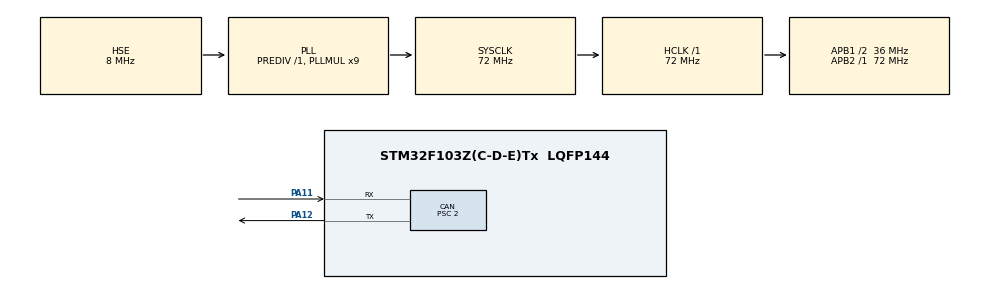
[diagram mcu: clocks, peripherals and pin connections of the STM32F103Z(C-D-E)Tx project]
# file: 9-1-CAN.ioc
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CAN.ABOM=ENABLE
CAN.BS1=CAN_BS1_13TQ
CAN.BS2=CAN_BS2_4TQ
CAN.CalculateBaudRate=1000000
CAN.CalculateTimeBit=1000
CAN.CalculateTimeQuantum=55.55555555555556
CAN.NART=ENABLE
CAN.Prescaler=2
Mcu.Family=STM32F1
Mcu.Name=STM32F103Z(C-D-E)Tx
Mcu.Package=LQFP144
NVIC.CAN1_RX1_IRQn=true\:0\:0\:false\:false\:true\:true\:true\:true
NVIC.CAN1_SCE_IRQn=true\:0\:0\:false\:false\:true\:true\:true\:true
NVIC.PriorityGroup=NVIC_PRIORITYGROUP_4
OSC_IN.Mode=HSE-External-Oscillator
OSC_IN.Signal=RCC_OSC_IN
OSC_OUT.Mode=HSE-External-Oscillator
OSC_OUT.Signal=RCC_OSC_OUT
PA11.Mode=CAN_Activate
PA11.Signal=CAN_RX
PA12.Mode=CAN_Activate
PA12.Signal=CAN_TX
PA13.Mode=Serial_Wire
PA13.Signal=SYS_JTMS-SWDIO
PA14.Mode=Serial_Wire
PA14.Signal=SYS_JTCK-SWCLK
ProjectManager.HeapSize=0x200
ProjectManager.StackSize=0x400
ProjectManager.TargetToolchain=MDK-ARM V5.32
RCC.AHBFreq_Value=72000000
RCC.APB1CLKDivider=RCC_HCLK_DIV2
RCC.APB1Freq_Value=36000000
RCC.APB1TimFreq_Value=72000000
RCC.APB2Freq_Value=72000000
RCC.APB2TimFreq_Value=72000000
RCC.HCLKFreq_Value=72000000
RCC.PLLMUL=RCC_PLL_MUL9
RCC.PLLSourceVirtual=RCC_PLLSOURCE_HSE
RCC.SYSCLKFreq_VALUE=72000000
RCC.SYSCLKSource=RCC_SYSCLKSOURCE_PLLCLK
RCC.USBFreq_Value=72000000
board=custom

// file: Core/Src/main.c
/* USER CODE BEGIN Header */
/**
  ******************************************************************************
  * @file           : main.c
  * @brief          : Main program body
  ******************************************************************************
  * @attention
  *
  * Copyright (c) 2026 STMicroelectronics.
  * All rights reserved.
  *
  * This software is licensed under terms that can be found in the LICENSE file
  * in the root directory of this software component.
  * If no LICENSE file comes with this software, it is provided AS-IS.
  *
  ******************************************************************************
  */
/* USER CODE END Header */
#include "main.h"
#include "can.h"
#include "gpio.h"

void SystemClock_Config(void);

int main(void)
{

  /* MCU Configuration--------------------------------------------------------*/

  /* Reset of all peripherals, Initializes the Flash interface and the Systick. */
  HAL_Init();

  /* Configure the system clock */
  SystemClock_Config();

  /* Initialize all configured peripherals */
  MX_GPIO_Init();
  MX_CAN_Init();
  /* USER CODE BEGIN 2 */

CAN_FilterTypeDef can_filter;
can_filter.FilterBank = 0;
can_filter.FilterMode = CAN_FILTERMODE_IDMASK;
can_filter.FilterScale = CAN_FILTERSCALE_32BIT;
can_filter.FilterIdHigh = 0x0000;
can_filter.FilterIdLow = 0x0000;
can_filter.FilterMaskIdHigh = 0x0000;
can_filter.FilterMaskIdLow = 0x0000; // 全 0 表示接收所有 ID
can_filter.FilterFIFOAssignment = CAN_RX_FIFO0;
can_filter.FilterActivation = ENABLE;

HAL_CAN_ConfigFilter(&hcan, &can_filter); // 配置过滤器
HAL_CAN_Start(&hcan);                     // 开启 CAN
HAL_CAN_ActivateNotification(&hcan, CAN_IT_RX_FIFO0_MSG_PENDING); // 开启中断接收

  /* USER CODE END 2 */

  /* Infinite loop */
  while (1)
  {

  }
}

void SystemClock_Config(void)
{
  RCC_OscInitTypeDef RCC_OscInitStruct = {0};
  RCC_ClkInitTypeDef RCC_ClkInitStruct = {0};

  /** Initializes the RCC Oscillators according to the specified parameters
  * in the RCC_OscInitTypeDef structure.
  */
  RCC_OscInitStruct.OscillatorType = RCC_OSCILLATORTYPE_HSE;
  RCC_OscInitStruct.HSEState = RCC_HSE_ON;
  RCC_OscInitStruct.HSEPredivValue = RCC_HSE_PREDIV_DIV1;
  RCC_OscInitStruct.HSIState = RCC_HSI_ON;
  RCC_OscInitStruct.PLL.PLLState = RCC_PLL_ON;
  RCC_OscInitStruct.PLL.PLLSource = RCC_PLLSOURCE_HSE;
  RCC_OscInitStruct.PLL.PLLMUL = RCC_PLL_MUL9;
  if (HAL_RCC_OscConfig(&RCC_OscInitStruct) != HAL_OK)
  {
    Error_Handler();
  }

  /** Initializes the CPU, AHB and APB buses clocks
  */
  RCC_ClkInitStruct.ClockType = RCC_CLOCKTYPE_HCLK|RCC_CLOCKTYPE_SYSCLK
                              |RCC_CLOCKTYPE_PCLK1|RCC_CLOCKTYPE_PCLK2;
  RCC_ClkInitStruct.SYSCLKSource = RCC_SYSCLKSOURCE_PLLCLK;
  RCC_ClkInitStruct.AHBCLKDivider = RCC_SYSCLK_DIV1;
  RCC_ClkInitStruct.APB1CLKDivider = RCC_HCLK_DIV2;
  RCC_ClkInitStruct.APB2CLKDivider = RCC_HCLK_DIV1;

  if (HAL_RCC_ClockConfig(&RCC_ClkInitStruct, FLASH_LATENCY_2) != HAL_OK)
  {
    Error_Handler();
  }
}

void Error_Handler(void)
{
  __disable_irq();
  while (1)
  {
  }
}
